# STM32C562xx register map
File version: 1.0
Registers are 32-bit, read-write, reset 0x0 unless marked. A register's access mark holds for its fields unless they carry their own. Offsets are from the block's base; [hi:lo] are bit positions; {n}, {i} and the like mark numbered series.

## GPIOA — General Purpose I/O (GPIO)
Base 0x42020000
Same registers: GPIOB 0x42020400, GPIOC 0x42020800, GPIOD 0x42020C00, GPIOE 0x42021000, GPIOH 0x42021C00
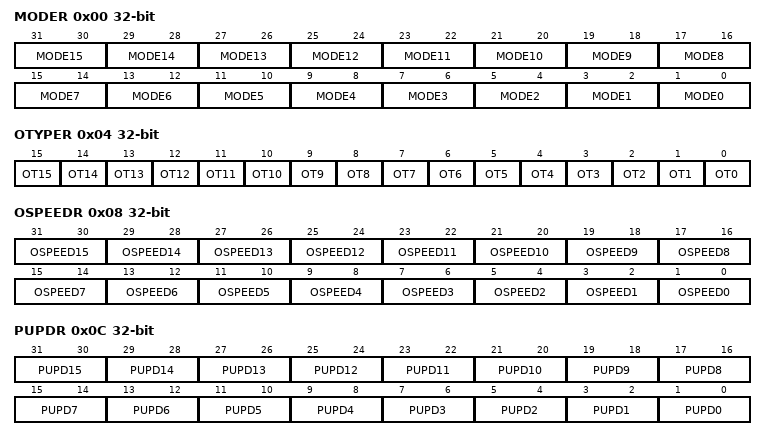
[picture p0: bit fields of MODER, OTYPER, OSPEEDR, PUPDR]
0x00 MODER — GPIO port mode register
  [2n+1:2n] MODE{n} (n=0..15) — Port x configuration I/O pin y
0x04 OTYPER — GPIO port output type register
  [n] OT{n} (n=0..15) — Port x configuration I/O pin y
0x08 OSPEEDR — GPIO port output speed register
  [2n+1:2n] OSPEED{n} (n=0..15) — Port x configuration I/O pin y
0x0C PUPDR — GPIO port pull-up/pull-down register
  [2n+1:2n] PUPD{n} (n=0..15) — Port x configuration I/O pin y
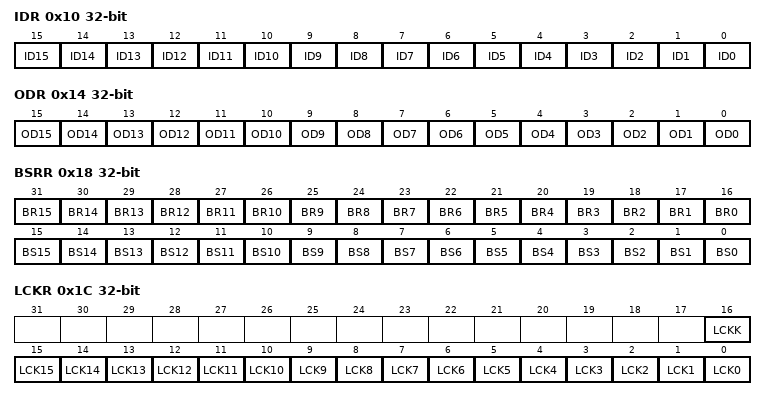
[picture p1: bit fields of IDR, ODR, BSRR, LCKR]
0x10 IDR ro — GPIO port input data register
  [n] ID{n} (n=0..15) — Port x input data I/O pin y
0x14 ODR — GPIO port output data register
  [n] OD{n} (n=0..15) — Port output data I/O pin y
0x18 BSRR — GPIO port bit set/reset register
  [n+16] BR{n} (n=0..15) — Port x reset I/O pin y
  [n] BS{n} (n=0..15) — Port x set I/O pin y
0x1C LCKR — GPIO port configuration lock register
  [16] LCKK — Lock key
  [n] LCK{n} (n=0..15) — Port x lock I/O pin y
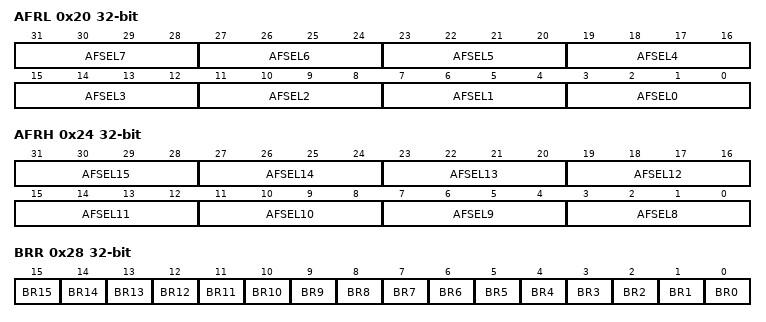
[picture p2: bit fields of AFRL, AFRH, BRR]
0x20 AFRL — GPIO alternate function register
  [4n+3:4n] AFSEL{n} (n=0..7)
0x24 AFRH — GPIO alternate function register
  [4n-29:4n-32] AFSEL{n} (n=8..15)
0x28 BRR — GPIO port bit reset register
  [n] BR{n} (n=0..15) — Port x reset IO pin y

## ADC12_COMMON
Base 0x42028300
0x00 CSR ro — ADC common status register
0x08 CCR — ADC common control register
0x0C CDR ro — ADC common regular data register for dual mode
0x10 CDR2 ro — ADC common regular data register for dual mode

## DAC1 — Digital to Analog Converter
Base 0x42028400
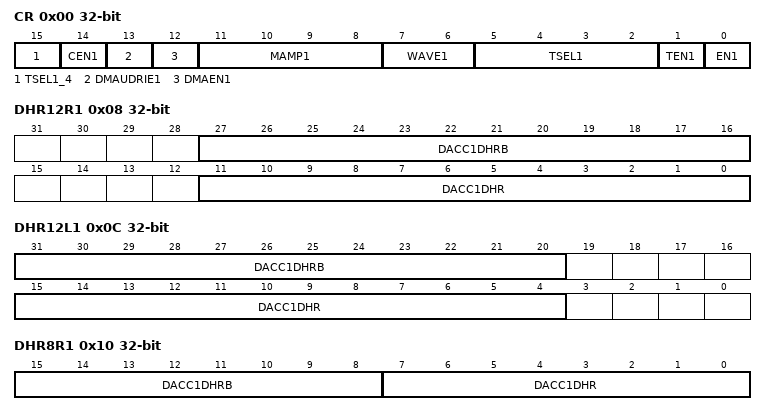
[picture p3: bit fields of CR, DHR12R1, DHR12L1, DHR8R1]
0x00 CR — DAC control register
  [15] TSEL1_4 — DAC channel1 trigger selection
  [14] CEN1 — DAC channel1 calibration enable
  [13] DMAUDRIE1
  [12] DMAEN1 — DAC channel1 DMA enable
  [11:8] MAMP1 — DAC channel1 mask/amplitude selector
  [7:6] WAVE1
  [5:2] TSEL1 — DAC channel1 trigger selection
  [1] TEN1 — DAC channel1 trigger enable
  [0] EN1 — DAC channel1 enable
0x04 SWTRGR — DAC software trigger register
  [0] SWTRIG1
0x08 DHR12R1 — DAC channel1 12-bit right-aligned data holding register
  [27:16] DACC1DHRB, [11:0] DACC1DHR
0x0C DHR12L1 — DAC channel1 12-bit left aligned data holding register
  [31:20] DACC1DHRB
  [15:4] DACC1DHR — DAC channel1 12-bit left-aligned data
0x10 DHR8R1 — DAC channel1 8-bit right aligned data holding register
  [15:8] DACC1DHRB — DAC channel1 8-bit right-aligned data
  [7:0] DACC1DHR — DAC channel1 8-bit right-aligned data
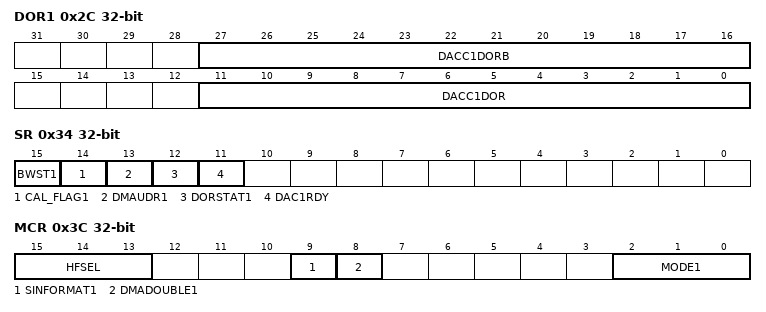
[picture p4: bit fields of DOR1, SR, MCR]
0x2C DOR1 ro — DAC channel1 data output register
  [27:16] DACC1DORB — DAC channel1 data output
  [11:0] DACC1DOR — DAC channel1 data output
0x34 SR — DAC status register
  [15] BWST1
  [14] CAL_FLAG1
  [13] DMAUDR1 — DAC channel1 DMA underrun flag
  [12] DORSTAT1
  [11] DAC1RDY — DAC channel1 ready status bit
0x38 CCR — DAC calibration control register
  [4:0] OTRIM1 — DAC channel1 offset trimming value
0x3C MCR — DAC mode control register
  [15:13] HFSEL
  [9] SINFORMAT1 — Enable signed format for DAC channel1
  [8] DMADOUBLE1 — DAC channel1 DMA double data mode
  [2:0] MODE1 — DAC channel1 mode
0x40 SHSR1 — DAC channel1 sample and hold sample time register
  [9:0] TSAMPLE1
0x48 SHHR — DAC sample and hold time register
  [9:0] THOLD1
0x4C SHRR — DAC sample and hold refresh time register
  [7:0] TREFRESH1

## AES — AES hardware accelerator (AES)
Base 0x420C0000
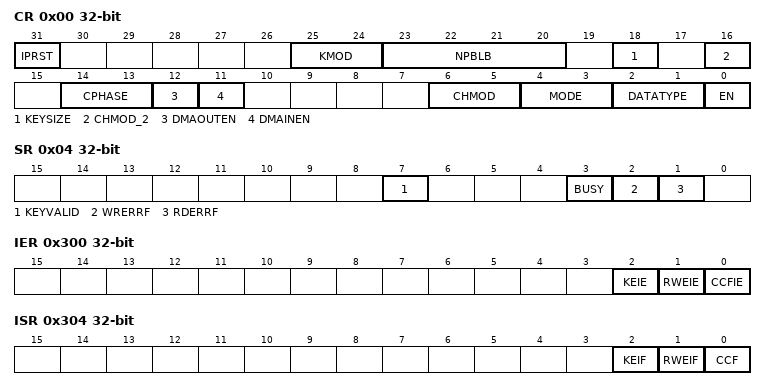
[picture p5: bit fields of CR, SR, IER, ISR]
0x00 CR — AES control register
  [31] IPRST — AES peripheral software reset
  [25:24] KMOD — Key mode selection
  [23:20] NPBLB
  [18] KEYSIZE — Key size selection
  [16] CHMOD_2 — AES Chaining Mode
  [14:13] CPHASE — Chaining phase selection
  [12] DMAOUTEN — DMA output enable
  [11] DMAINEN — DMA input enable
  [6:5] CHMOD — AES Chaining Mode
  [4:3] MODE — Operating mode
  [2:1] DATATYPE
  [0] EN — Enable
0x04 SR ro — AES status register
  [7] KEYVALID — Key valid flag
  [3] BUSY — Busy Flag
  [2] WRERRF — Write error flag
  [1] RDERRF — Read error flag
0x08 DINR — AES data input register
  [31:0] DIN — Data input
0x0C DOUTR ro — AES data output register
  [31:0] DOUT — Data output
{0x10+4i} KEYR{i} (i=0..3) — AES key register {i}
  [31:0] KEY — Cryptographic key, bits [{32i+31}:{32i}]
{0x20+4i} IVR{i} (i=0..3) — AES initialization vector register {i}
  [31:0] IVI
{0x20+4i} KEYR{i} (i=4..7) — AES key register {i}
  [31:0] KEY — Cryptographic key, bits [{32i+31}:{32i}]
{0x40+4i} SUSPR{i} (i=0..7) — AES suspend registers
  [31:0] SUSP — Suspend data
0x300 IER — AES interrupt enable register
  [2] KEIE — Key error interrupt enable
  [1] RWEIE
  [0] CCFIE
0x304 ISR ro — AES interrupt status register
  [2] KEIF — Key error interrupt flag
  [1] RWEIF
  [0] CCF — Computation complete flag
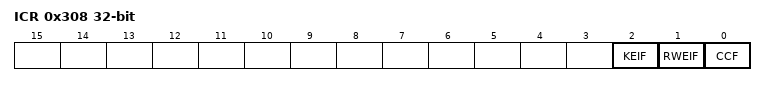
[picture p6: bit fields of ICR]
0x308 ICR — AES interrupt clear register
  [2] KEIF — Key error interrupt flag clear
  [1] RWEIF
  [0] CCF — Computation complete flag clear
